# STM32N645 register map
File version: 1.0
CPU: CM55 r0p1, little endian, no MPU, FPU, vendor SysTick, 8 interrupt priority bits
Registers are 32-bit, read-write, reset 0x0 unless marked. A register's access mark holds for its fields unless they carry their own. Offsets are from the block's base; [hi:lo] are bit positions; {n}, {i} and the like mark numbered series.

## RNG — True random number generator
Base 0x44020000
Same registers: RNG_S 0x54020000
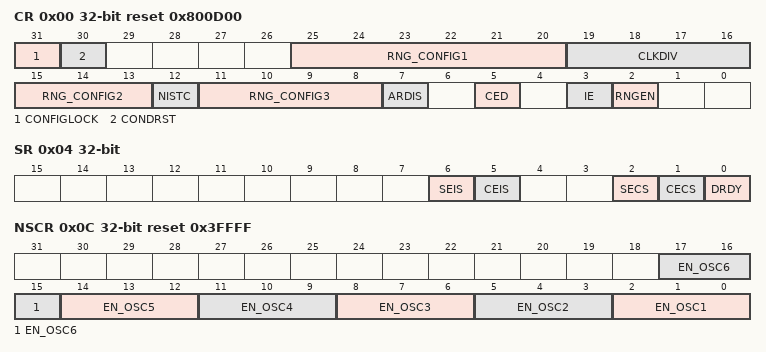
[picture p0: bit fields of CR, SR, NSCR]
0x00 CR reset 0x800D00 — RNG control register
  [31] CONFIGLOCK — RNG Config lock
    0=Enabled (Writes to the RNG_CR configuration bits [29:4] are allowed); 1=Disabled (Writes to the RNG_CR configuration bits [29:4] are ignored until the next RNG reset)
  [30] CONDRST — Conditioning soft reset
  [25:20] RNG_CONFIG1 — RNG configuration 1
    15=ConfigA (Recommended value for config A (NIST certifiable)); 24=ConfigB (Recommended value for config B (not NIST certifiable))
  [19:16] CLKDIV — Clock divider factor
    0=Div1 (Internal RNG clock after divider is similar to incoming RNG clock); 1=Div2 (Divide RNG clock by 2^1); 2=Div4 (Divide RNG clock by 2^2); 3=Div8 (Divide RNG clock by 2^3); 4=Div16 (Divide RNG clock by 2^4); 5=Div32 (Divide RNG clock by 2^5); 6=Div64 (Divide RNG clock by 2^6); 7=Div128 (Divide RNG clock by 2^7); 8=Div256 (Divide RNG clock by 2^8); 9=Div512 (Divide RNG clock by 2^9); 10=Div1024 (Divide RNG clock by 2^10); 11=Div2048 (Divide RNG clock by 2^11); 12=Div4096 (Divide RNG clock by 2^12); 13=Div8192 (Divide RNG clock by 2^13); 14=Div16384 (Divide RNG clock by 2^14); 15=Div32768 (Divide RNG clock by 2^15)
  [15:13] RNG_CONFIG2 — RNG configuration 2
    0=ConfigA_B (Recommended value for config A and B)
  [12] NISTC — NIST custom
    0=Default (Hardware default values for NIST compliant RNG. In this configuration per 128-bit output two conditioning loops are performed and 256 bits of noise source are used); 1=Custom values for NIST compliant RNG
  [11:8] RNG_CONFIG3 — RNG configuration 3
    0=ConfigB (Recommended value for config B (not NIST certifiable)); 13=ConfigA (Recommended value for config A (NIST certifiable))
  [7] ARDIS — Auto reset disable
  [5] CED — Clock error detection
    0=Enabled (Clock error detection is enabled); 1=Disabled (Clock error detection is disabled)
  [3] IE — Interrupt enable
    0=Disabled (RNG interrupt is disabled); 1=Enabled (RNG interrupt is enabled)
  [2] RNGEN — True random number generator enable
    0=Disabled (Random number generator is disabled); 1=Enabled (Random number generator is enabled)
0x04 SR access per field — RNG status register
  [6] SEIS rw write-0-clears — Seed error interrupt status
    on write: 0=Clear flag | on read: 0=No faulty sequence detected; 1=Fault (At least one faulty sequence has been detected. See **SECS** bit description for details. An interrupt is pending if IE = 1 in the RNG_CR register.)
  [5] CEIS rw write-0-clears — Clock error interrupt status
    on write: 0=Clear flag | on read: 0=Correct (The RNG clock is correct); 1=Slow (The RNG has been detected too slow An interrupt is pending if IE = 1 in the RNG_CR register)
  [2] SECS ro — Seed error current status
    0=No faulty sequence has currently been detected. If the SEIS bit is set, this means that a faulty sequence was detected and the situation has been recovered.; 1=Fault (At least one faulty sequence has been detected - see ref manual for details)
  [1] CECS ro — Clock error current status
    0=Correct (The RNG clock is correct. If the CEIS bit is set, this means that a slow clock was detected and the situation has been recovered.); 1=Slow (The RNG clock is too slow)
  [0] DRDY ro — Data ready
    0=Invalid (The RNG_DR register is not yet valid, no random data is available); 1=Valid (The RNG_DR register contains valid random data. Once the RNG_DR register has been read, this bit returns to 0 until a new random value is generated.)
0x08 DR ro — RNG data register
  [31:0] RNDATA — Random data
0x0C NSCR reset 0x3FFFF — RNG noise source control register
  [3n-1:3n-3] EN_OSC{n} (n=1..6) — Each bit drives one oscillator enable signal input of instance number {n}, gated with the RNGEN bit in RNG_CR (set bit to enable the oscillator). Bit is ignored otherwise.
0x10 HTCR reset 0x72AC — RNG health test control register
  [31:0] HTCFG — health test configuration
    0xAA74=Recommended value for RNG certification (0x0000_AA74); 0x17590ABC=Magic number to be written before any write (0x1759_0ABC)
